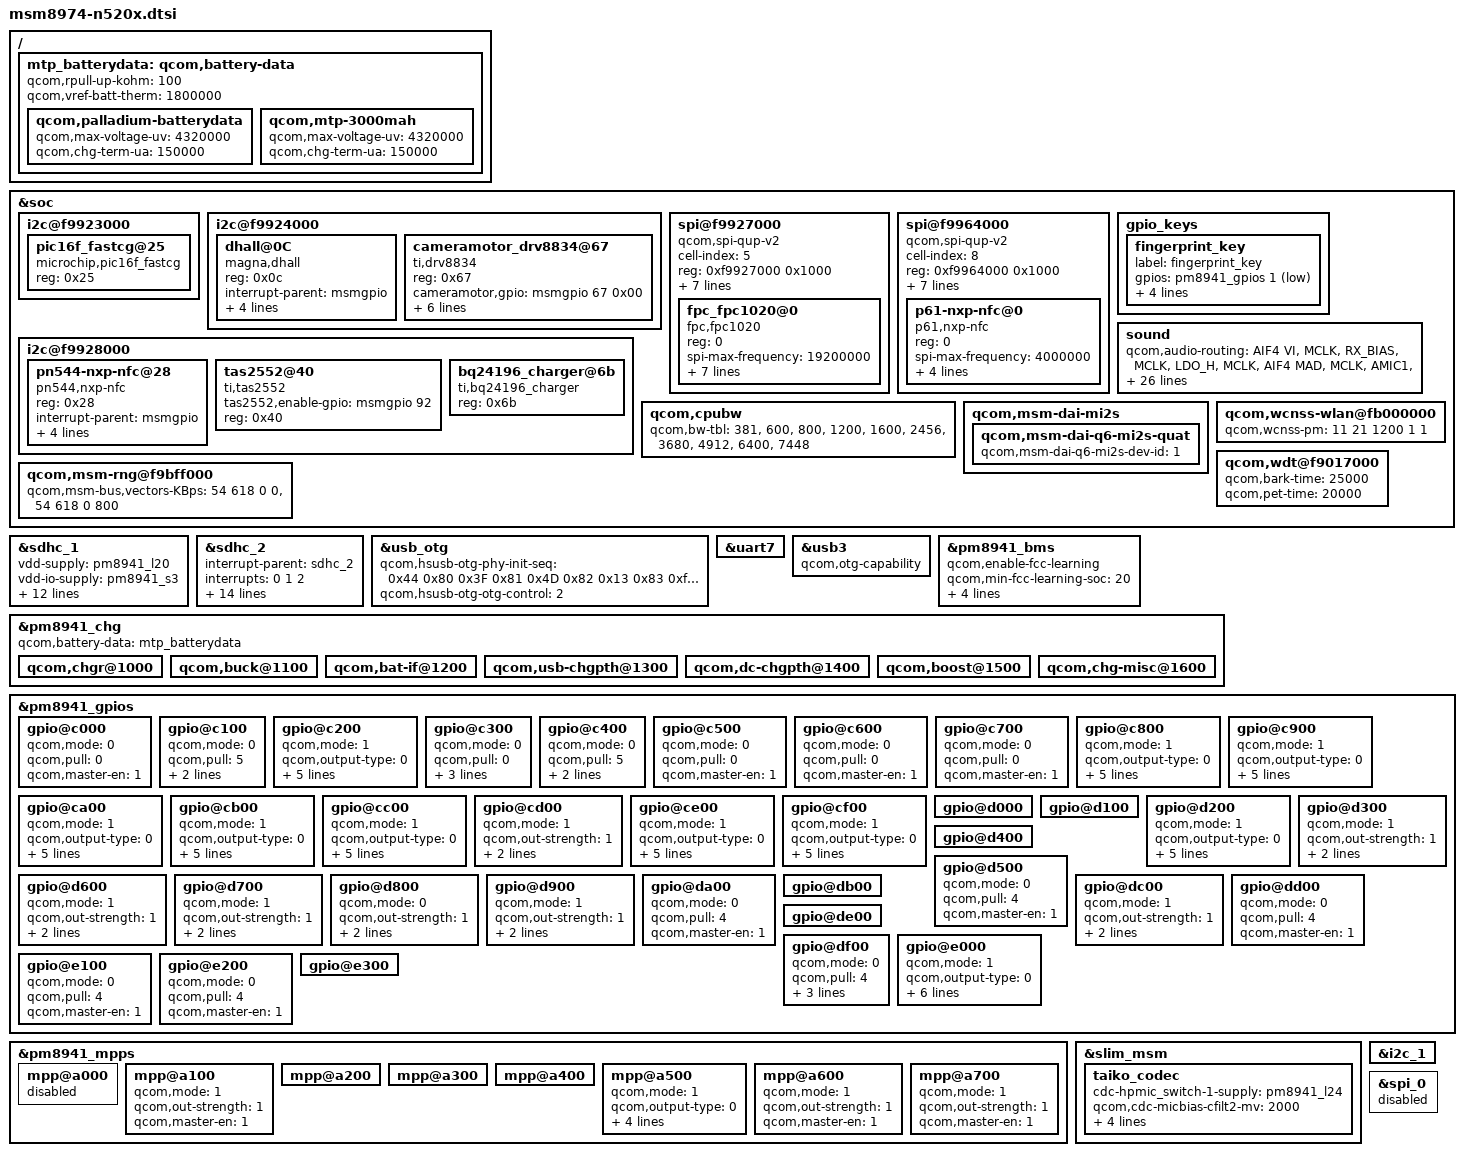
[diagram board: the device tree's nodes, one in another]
/* Copyright (c) 2012-2013, The Linux Foundation. All rights reserved.
 *
 * This program is free software; you can redistribute it and/or modify
 * it under the terms of the GNU General Public License version 2 and
 * only version 2 as published by the Free Software Foundation.
 *
 * This program is distributed in the hope that it will be useful,
 * but WITHOUT ANY WARRANTY; without even the implied warranty of
 * MERCHANTABILITY or FITNESS FOR A PARTICULAR PURPOSE.  See the
 * GNU General Public License for more details.
 */

/include/ "msm8974-oppo-common.dtsi"
/include/ "msm8974-oppo-camera.dtsi"
/include/ "msm8974-n520x-camera-sensor.dtsi"
/include/ "msm8974-oppo-input.dtsi"
/include/ "msm8974-oppo-usb.dtsi"
/include/ "msm8974-oppo-misc.dtsi"
/include/ "msm8974-oppo-pm.dtsi"
/include/ "msm8974-oppo-nfc.dtsi"
/include/ "msm8974-oppo-regulator.dtsi"
/include/ "msm8974-oppo-sound.dtsi"
/include/ "msm8974-oppo-leds.dtsi"
/include/ "msm8974-n520x-leds.dtsi"
/include/ "msm8974-n520x-mdss.dtsi"

&soc {
	i2c@f9923000 {
		pic16f_fastcg@25 {
			status = "okay";
			compatible = "microchip,pic16f_fastcg";
			reg = <0x25>;
		};
	};

	i2c@f9924000 {
		dhall@0C {
			compatible = "magna,dhall";
			reg = <0x0c>;
			interrupt-parent = <&msmgpio>;
			interrupts = <64 0x4>;
			dhall,irq-gpio = <&msmgpio 64 0x2008>;
			vdd_2v8-supply = <&pm8941_l17>;
			vcc_i2c_1v8-supply = <&pm8941_lvs2>;
		};

		cameramotor_drv8834@67 {
			compatible = "ti,drv8834";
			reg = <0x67>;
			cameramotor,gpio = <&msmgpio 67 0x00>;
			qcom,platform-vref-gpio = <&pm8941_gpios 9 0>;
			qcom,platform-sleep-gpio = <&pm8941_gpios 10 0>;
			qcom,platform-dir-gpio = <&pm8941_gpios 11 0>;
			qcom,platform-m0-gpio = <&pm8941_gpios 12 0>;
			qcom,platform-m1-gpio = <&pm8941_gpios 13 0>;
			qcom,platform-step-gpio = <&pm8941_gpios 33 0>;
		};
	};

	spi@f9927000 {
		compatible = "qcom,spi-qup-v2";

		cell-index = <5>;
		reg-names = "spi_physical";
		reg = <0xf9927000 0x1000>;
		interrupt-names = "spi5_irq";
		interrupts = <0 99 0>;

		spi-max-frequency = <9600000>;
		#address-cells = <1>;
		#size-cells = <0>;

		qcom,gpio-mosi = <&msmgpio 23 0>;
		qcom,gpio-miso = <&msmgpio 24 0>;
		qcom,gpio-clk  = <&msmgpio 26 0>;
		qcom,gpio-cs0  = <&msmgpio 25 0>;

		qcom,master-id = <86>;

		fpc_fpc1020@0 {
			compatible = "fpc,fpc1020";
			reg = <0>;
			spi-max-frequency = <19200000>;
			interrupt-parent = <&msmgpio>;
			interrupts = <102 0>;
			fpc,gpio_irq = <&msmgpio 102 0x00>;
			fpc,gpio_reset = <&msmgpio 84 0x00>; 
			fpc,gpio_envdd = <&msmgpio 16 0x00>;
			fpc,vddtx_mv;
			vdd_io-supply = <&pm8941_s3>;
		};
	};

	i2c@f9928000 {
		pn544-nxp-nfc@28 {
			compatible = "pn544,nxp-nfc";
			reg = <0x28>;
			interrupt-parent = <&msmgpio>;
			interrupts = <59 0x4>;
			pn544,irq-gpio = <&msmgpio 59 0x00>;
			pn544,enable-gpio = <&msmgpio 13 0x00>;
			pn544,update-gpio = <&msmgpio 12 0x00>;
		};

		tas2552@40 {
			status = "okay";
			compatible = "ti,tas2552";
			tas2552,enable-gpio = <&msmgpio 92 0x00>;
			reg = <0x40>;
		};

		bq24196_charger@6b {
			status = "okay";
			compatible = "ti,bq24196_charger";
			reg = <0x6b>;
		};
	};

	spi@f9964000 {
		compatible = "qcom,spi-qup-v2";

		cell-index = <8>;
		reg-names = "spi_physical";
		reg = <0xf9964000 0x1000>;
		interrupt-names = "spi8_irq";
		interrupts = <0 102 0>;

		spi-max-frequency = <19200000>;
		#address-cells = <1>;
		#size-cells = <0>;

		qcom,gpio-mosi = <&msmgpio 45 0>;
		qcom,gpio-miso = <&msmgpio 46 0>;
		qcom,gpio-clk  = <&msmgpio 48 0>;
		qcom,gpio-cs0  = <&msmgpio 47 0>;

		qcom,master-id = <84>;

		p61-nxp-nfc@0 {
			compatible = "p61,nxp-nfc";
			reg = <0>;
			spi-max-frequency = <4000000>;
			spi-cs-high;
			interrupt-parent = <&msmgpio>;
			interrupts = <34 0>;
			p61-nxp-nfc,irq-gpio = <&msmgpio 34 0x00>;
		};
	};

	gpio_keys {

		fingerprint_key {
			label = "fingerprint_key";
			gpios = <&pm8941_gpios 1 0x1>;
			linux,input-type = <1>;
			linux,code = <120>;
			gpio-key,wakeup;
			debounce-interval = <15>;
		};
	};

	sound {
		qcom,audio-routing =
			"AIF4 VI", "MCLK",
			"RX_BIAS", "MCLK",
			"LDO_H", "MCLK",
			"AIF4 MAD", "MCLK",
			"AMIC1", "MIC BIAS1 Internal1",
			"MIC BIAS1 Internal1", "Handset Mic",
			"AMIC2", "MIC BIAS2 External",
			"MIC BIAS2 External", "Headset Mic",
			"AMIC3", "MIC BIAS1 External",
			"MIC BIAS1 External", "Main Mic",
			"AMIC4", "MIC BIAS1 External",
			"MIC BIAS1 External", "Second Mic",
			"AMIC5", "MIC BIAS1 External",
			"MIC BIAS1 External", "ANC Mic",
			"DMIC1", "MIC BIAS1 External",
			"MIC BIAS1 External", "Digital Mic1",
			"DMIC2", "MIC BIAS1 External",
			"MIC BIAS1 External", "Digital Mic2",
			"DMIC3", "MIC BIAS3 External",
			"MIC BIAS3 External", "Digital Mic3",
			"DMIC4", "MIC BIAS3 External",
			"MIC BIAS3 External", "Digital Mic4",
			"DMIC5", "MIC BIAS4 External",
			"MIC BIAS4 External", "Digital Mic5",
			"DMIC6", "MIC BIAS4 External",
			"MIC BIAS4 External", "Digital Mic6",
			"Lineout_1 amp", "LINEOUT1",
			"Lineout_3 amp", "LINEOUT3";

		qcom,model = "msm8974-taiko-mtp-snd-card";
		qcom,cdc-micbias2-headset-only;
		qcom,mbhc-audio-jack-type = "4-pole-jack";
		qcom,us-euro-gpios = <&msmgpio 87 0>;
		qcom,yda145_ctr-gpio = <&msmgpio 77 0>;
		qcom,yda145_boost-gpio = <&msmgpio 67 0>;
		enable_spk-gpio = <&msmgpio 73 0>;
		cdc_spk-supply = <&pm8941_boost>;
	};

	qcom,cpubw {
		qcom,bw-tbl =
			<  381 /*  50 MHz */ >,
			<  600 /*  75 MHz */ >,
			<  800 /* 100 MHz */ >,
			< 1200 /* 150 MHz */ >,
			< 1600 /* 200 MHz */ >,
			< 2456 /* 307 MHz */ >,
			< 3680 /* 460 MHz */ >,
			< 4912 /* 614 MHz */ >,
			< 6400 /* 800 MHz */ >,
			< 7448 /* 931 MHz */ >;
	};

	qcom,msm-dai-mi2s {
		qcom,msm-dai-q6-mi2s-quat {
			qcom,msm-dai-q6-mi2s-dev-id = <1>;
		};
	};

	qcom,wcnss-wlan@fb000000 {
		qcom,wcnss-pm = <11 21 1200 1 1>;
	};

	qcom,msm-rng@f9bff000 {
		qcom,msm-bus,vectors-KBps =
				<54 618 0 0>,
				<54 618 0 800>;
	};

	qcom,wdt@f9017000 {
		qcom,bark-time = <25000>;
		qcom,pet-time = <20000>;
	};
};

&sdhc_1 {
	vdd-supply = <&pm8941_l20>;
	vdd-io-supply = <&pm8941_s3>;

	qcom,vdd-always-on;
	qcom,vdd-lpm-sup;
	qcom,vdd-voltage-level = <2950000 2950000>;
	qcom,vdd-current-level = <800 500000>;

	qcom,vdd-io-always-on;
	qcom,vdd-io-voltage-level = <1800000 1800000>;
	qcom,vdd-io-current-level = <250 154000>;

	qcom,pad-pull-on = <0x0 0x3 0x3>; /* no-pull, pull-up, pull-up */
	qcom,pad-pull-off = <0x0 0x3 0x3>; /* no-pull, pull-up, pull-up */
	qcom,pad-drv-on = <0x4 0x4 0x4>; /* 10mA, 10mA, 10mA */
	qcom,pad-drv-off = <0x0 0x0 0x0>; /* 2mA, 2mA, 2mA */

	qcom,nonremovable;
	status = "ok";
};

&sdhc_2 {
	#address-cells = <0>;
	interrupt-parent = <&sdhc_2>;
	interrupts = <0 1 2>;
	#interrupt-cells = <1>;
	interrupt-map-mask = <0xffffffff>;
	interrupt-map = <0 &intc 0 125 0
			1 &intc 0 221 0
			2 &msmgpio 77 0x3>;
	interrupt-names = "hc_irq", "pwr_irq", "status_irq";
	cd-gpios = <&msmgpio 77 0x1>;

	vdd-supply = <&pm8941_l21>;
	vdd-io-supply = <&pm8941_l13>;

	qcom,vdd-voltage-level = <2950000 2950000>;
	qcom,vdd-current-level = <9000 800000>;

	qcom,vdd-io-voltage-level = <1800000 2950000>;
	qcom,vdd-io-current-level = <6 22000>;

	qcom,pad-pull-on = <0x0 0x3 0x3>; /* no-pull, pull-up, pull-up */
	qcom,pad-pull-off = <0x0 0x3 0x3>; /* no-pull, pull-up, pull-up */
	qcom,pad-drv-on = <0x4 0x4 0x4>; /* 10mA, 10mA, 10mA */
	qcom,pad-drv-off = <0x0 0x0 0x0>; /* 2mA, 2mA, 2mA */
	status = "ok";
};

/* Drive strength recommendations for clock line from hardware team is 10 mA.
 * But since the driver has been been using the below values from the start
 * without any problems, continue to use those.
 */

&sdhc_1 {
	qcom,pad-drv-on = <0x7 0x4 0x4>; /* 16mA, 10mA, 10mA */
};

&sdhc_2 {
	qcom,pad-drv-on = <0x7 0x4 0x4>; /* 16mA, 10mA, 10mA */
};

&usb_otg {
	qcom,hsusb-otg-phy-init-seq = <0x44 0x80 0x3F 0x81 0x4D 0x82 0x13 0x83 0xffffffff>;
	qcom,hsusb-otg-otg-control = <2>;
};

&uart7 {
	status = "ok";
};

&usb3 {
	qcom,otg-capability;
};

/ {
	mtp_batterydata: qcom,battery-data {
		qcom,rpull-up-kohm = <100>;
		qcom,vref-batt-therm = <1800000>;

		/include/ "../batterydata-palladium.dtsi"
		/include/ "../batterydata-mtp-3000mah.dtsi"
	};
};

&mtp_batterydata {
	qcom,palladium-batterydata {
		qcom,max-voltage-uv = <4320000>;
		qcom,chg-term-ua = <150000>;
	};

	qcom,mtp-3000mah {
		qcom,max-voltage-uv = <4320000>;
		qcom,chg-term-ua = <150000>;
	};
};

&pm8941_bms {
	qcom,enable-fcc-learning;
	qcom,min-fcc-learning-soc = <20>;
	qcom,min-fcc-ocv-pc = <30>;
	qcom,min-fcc-learning-samples = <5>;
	qcom,fcc-resolution = <10>;
	status = "ok";
	qcom,battery-data = <&mtp_batterydata>;
};

&pm8941_chg {
	status = "ok";
	qcom,battery-data = <&mtp_batterydata>;

	qcom,chgr@1000 {
		status = "ok";
	};

	qcom,buck@1100 {
		status = "ok";
	};

	qcom,bat-if@1200 {
		status = "ok";
	};

	qcom,usb-chgpth@1300 {
		status = "ok";
	};

	qcom,dc-chgpth@1400 {
		status = "ok";
	};

	qcom,boost@1500 {
		status = "ok";
	};

	qcom,chg-misc@1600 {
		status = "ok";
	};
};

&pm8941_gpios {
	gpio@c000 { /* GPIO 1 */
		qcom,mode = <0>;        /* QPNP_PIN_MODE_DIG_IN */
		qcom,pull = <0>;        /* QPNP_PIN_PULL_UP_30  */
		qcom,master-en = <1>;
	};

	gpio@c100 { /* GPIO 2 */
		qcom,mode = <0>;        /* QPNP_PIN_MODE_DIG_IN */
		qcom,pull = <5>;        /* QPNP_PIN_PULL_NO */
		qcom,vin-sel = <2>;     /* QPNP_PIN_VIN2 */
		qcom,src-sel = <0>;	/* QPNP_PIN_SEL_FUNC_CONSTANT */
	};

	gpio@c200 { /* GPIO 3 */
		qcom,mode = <1>;		/* QPNP_PIN_MODE_DIG_OUT */
		qcom,output-type = <0>;		/* QPNP_PIN_OUT_BUF_CMOS */
		qcom,pull = <5>;		/* QPNP_PIN_PULL_NO */
		qcom,vin-sel = <2>;		/* QPNP_PIN_VIN2 */
		qcom,out-strength = <3>;
		qcom,src-sel = <2>;
		qcom,master-en = <1>;
	};

	gpio@c300 { /* GPIO 4 */
		qcom,mode = <0>;        /* QPNP_PIN_MODE_DIG_IN */
		qcom,pull = <0>;        /* QPNP_PIN_PULL_UP_30  */
		qcom,vin-sel = <2>;     /* QPNP_PIN_VIN2  */
		qcom,src-sel = <0>;	/* QPNP_PIN_SEL_FUNC_CONSTANT */
		qcom,master-en = <1>;
	};

	gpio@c400 { /* GPIO 5 */
		qcom,mode = <0>;        /* QPNP_PIN_MODE_DIG_IN */
		qcom,pull = <5>;        /* QPNP_PIN_PULL_NO */
		qcom,vin-sel = <2>;     /* QPNP_PIN_VIN2 */
		qcom,src-sel = <0>;	/* QPNP_PIN_SEL_FUNC_CONSTANT */
	};

	gpio@c500 { /* GPIO 6 */
		qcom,mode = <0>;        /* QPNP_PIN_MODE_DIG_IN */
		qcom,pull = <0>;        /* QPNP_PIN_PULL_UP_30  */
		qcom,master-en = <1>;
	};

	gpio@c600 { /* GPIO 7 */
		qcom,mode = <0>;        /* QPNP_PIN_MODE_DIG_IN */
		qcom,pull = <0>;        /* QPNP_PIN_PULL_UP_30  */
		qcom,master-en = <1>;
	};

	gpio@c700 { /* GPIO 8 */
		qcom,mode = <0>;        /* QPNP_PIN_MODE_DIG_IN */
		qcom,pull = <0>;        /* QPNP_PIN_PULL_UP_30  */
		qcom,master-en = <1>;
	};

	gpio@c800 { /* GPIO 9 */
		qcom,mode = <1>;		/* QPNP_PIN_MODE_DIG_OUT */
		qcom,output-type = <0>;		/* QPNP_PIN_OUT_BUF_CMOS */
		qcom,pull = <5>;		/* QPNP_PIN_PULL_NO */
		qcom,vin-sel = <0>;		/* QPNP_PIN_VIN2 VPH_PWR */
		qcom,out-strength = <1>;	/* QPNP_PIN_OUT_STRENGTH_LOW */
		qcom,src-sel = <0>;		/* QPNP_PIN_SEL_FUNC_CONSTANT */
		qcom,master-en = <0>;
	};

	gpio@c900 { /* GPIO 10 */
		qcom,mode = <1>;		/* QPNP_PIN_MODE_DIG_OUT */
		qcom,output-type = <0>;		/* QPNP_PIN_OUT_BUF_CMOS */
		qcom,pull = <5>;		/* QPNP_PIN_PULL_NO */
		qcom,vin-sel = <0>;		/* QPNP_PIN_VIN2 */
		qcom,out-strength = <1>;	/* QPNP_PIN_OUT_STRENGTH_LOW */
		qcom,src-sel = <0>;		/* QPNP_PIN_SEL_FUNC_CONSTANT */
		qcom,master-en = <1>;
	};

	gpio@ca00 { /* GPIO 11 */
		qcom,mode = <1>;		/* QPNP_PIN_MODE_DIG_OUT */
		qcom,output-type = <0>;		/* QPNP_PIN_OUT_BUF_CMOS */
		qcom,pull = <5>;		/* QPNP_PIN_PULL_NO */
		qcom,vin-sel = <0>;		/* QPNP_PIN_VIN2 */
		qcom,out-strength = <1>;	/* QPNP_PIN_OUT_STRENGTH_LOW */
		qcom,src-sel = <0>;		/* QPNP_PIN_SEL_FUNC_CONSTANT */
		qcom,master-en = <1>;
	};

	gpio@cb00 { /* GPIO 12 */
		qcom,mode = <1>;		/* QPNP_PIN_MODE_DIG_OUT */
		qcom,output-type = <0>;		/* QPNP_PIN_OUT_BUF_CMOS */
		qcom,pull = <5>;		/* QPNP_PIN_PULL_NO */
		qcom,vin-sel = <0>;		/* QPNP_PIN_VIN2 */
		qcom,out-strength = <1>;	/* QPNP_PIN_OUT_STRENGTH_LOW */
		qcom,src-sel = <0>;		/* QPNP_PIN_SEL_FUNC_CONSTANT */
		qcom,master-en = <1>;
	};

	gpio@cc00 { /* GPIO 13 */
		qcom,mode = <1>;		/* QPNP_PIN_MODE_DIG_OUT */
		qcom,output-type = <0>;		/* QPNP_PIN_OUT_BUF_CMOS */
		qcom,pull = <5>;		/* QPNP_PIN_PULL_NO */
		qcom,vin-sel = <0>;		/* QPNP_PIN_VIN2 */
		qcom,out-strength = <1>;	/* QPNP_PIN_OUT_STRENGTH_LOW */
		qcom,src-sel = <0>;		/* QPNP_PIN_SEL_FUNC_CONSTANT */
		qcom,master-en = <1>;
	};

	gpio@cd00 { /* GPIO 14 */
		qcom,mode = <1>;          /* QPNP_PIN_MODE_DIG_OUT */
		qcom,out-strength = <1>;  /* QPNP_PIN_OUT_STRENGTH_LOW */
		qcom,src-sel = <2>;       /* QPNP_PIN_SEL_FUNC_1  */
		qcom,master-en = <1>;
	};

	gpio@ce00 { /* GPIO 15 */
		qcom,mode = <1>;
		qcom,output-type = <0>;
		qcom,pull = <5>;
		qcom,vin-sel = <2>;
		qcom,out-strength = <1>;
		qcom,src-sel = <2>;
		qcom,master-en = <1>;
	};

	gpio@cf00 { /* GPIO 16 */
		qcom,mode = <1>;
		qcom,output-type = <0>;
		qcom,pull = <5>;
		qcom,vin-sel = <2>;
		qcom,out-strength = <3>;
		qcom,src-sel = <3>;       /* QPNP_PIN_SEL_FUNC_2  */
		qcom,master-en = <1>;
	};

	gpio@d000 { /* GPIO 17 */
	};

	gpio@d100 { /* GPIO 18 */
	};

	gpio@d200 { /* GPIO 19 */
		qcom,mode = <1>;		/* QPNP_PIN_MODE_DIG_OUT */
		qcom,output-type = <0>;		/* QPNP_PIN_OUT_BUF_CMOS */
		qcom,pull = <5>;		/* QPNP_PIN_PULL_NO */
		qcom,vin-sel = <2>;		/* QPNP_PIN_VIN2 */
		qcom,out-strength = <1>;	/* QPNP_PIN_OUT_STRENGTH_LOW */
		qcom,src-sel = <0>;		/* QPNP_PIN_SEL_FUNC_CONSTANT */
		qcom,master-en = <1>;
	};

	gpio@d300 { /* GPIO 20 */
		qcom,mode = <1>;          /* QPNP_PIN_MODE_DIG_OUT */
		qcom,out-strength = <1>;  /* QPNP_PIN_OUT_STRENGTH_LOW */
		qcom,src-sel = <2>;       /* QPNP_PIN_SEL_FUNC_1  */
		qcom,master-en = <1>;
	};

	gpio@d400 { /* GPIO 21 */
	};

	gpio@d500 { /* GPIO 22 */
		qcom,mode = <0>;        /* QPNP_PIN_MODE_DIG_IN */
		qcom,pull = <4>;	/* QPNP_PIN_PULL_DN */
		qcom,master-en = <1>;
	};

	gpio@d600 { /* GPIO 23 */
		qcom,mode = <1>;          /* QPNP_PIN_MODE_DIG_OUT */
		qcom,out-strength = <1>;  /* QPNP_PIN_OUT_STRENGTH_LOW */
		qcom,src-sel = <2>;       /* QPNP_PIN_SEL_FUNC_1  */
		qcom,master-en = <1>;
	};

	gpio@d700 { /* GPIO 24 */
		qcom,mode = <1>;          /* QPNP_PIN_MODE_DIG_OUT */
		qcom,out-strength = <1>;  /* QPNP_PIN_OUT_STRENGTH_LOW */
		qcom,src-sel = <2>;       /* QPNP_PIN_SEL_FUNC_1  */
		qcom,master-en = <1>;
	};

	gpio@d800 { /* GPIO 25 */
		qcom,mode = <0>;          /* QPNP_PIN_MODE_DIG_IN */
		qcom,out-strength = <1>;  /* QPNP_PIN_OUT_STRENGTH_LOW */
		qcom,src-sel = <2>;       /* QPNP_PIN_SEL_FUNC_1  */
		qcom,master-en = <1>;
	};

	gpio@d900 { /* GPIO 26 */
		qcom,mode = <1>;          /* QPNP_PIN_MODE_DIG_OUT */
		qcom,out-strength = <1>;  /* QPNP_PIN_OUT_STRENGTH_LOW */
		qcom,src-sel = <2>;       /* QPNP_PIN_SEL_FUNC_1  */
		qcom,master-en = <1>;
	};

	gpio@da00 { /* GPIO 27 */
		qcom,mode = <0>;        /* QPNP_PIN_MODE_DIG_IN */
		qcom,pull = <4>;	/* QPNP_PIN_PULL_DN */
		qcom,master-en = <1>;
	};

	gpio@db00 { /* GPIO 28 */
	};

	gpio@dc00 { /* GPIO 29 */
		qcom,mode = <1>;          /* QPNP_PIN_MODE_DIG_OUT */
		qcom,out-strength = <1>;  /* QPNP_PIN_OUT_STRENGTH_LOW */
		qcom,src-sel = <2>;       /* QPNP_PIN_SEL_FUNC_1  */
		qcom,master-en = <1>;
	};

	gpio@dd00 { /* GPIO 30 */
		qcom,mode = <0>;        /* QPNP_PIN_MODE_DIG_IN */
		qcom,pull = <4>;	/* QPNP_PIN_PULL_DN */
		qcom,master-en = <1>;
	};

	gpio@de00 { /* GPIO 31 */
	};

	gpio@df00 { /* GPIO 32 */
		qcom,mode = <0>;        /* QPNP_PIN_MODE_DIG_IN */
		qcom,pull = <4>;	/* QPNP_PIN_PULL_DN */
		qcom,vin-sel = <2>;     /* QPNP_PIN_VIN2  */
		qcom,src-sel = <0>;     /* QPNP_PIN_SEL_FUNC_CONSTANT */
		qcom,master-en = <1>;
	};

	gpio@e000 { /* GPIO 33 */
		qcom,mode = <1>;	/* QPNP_PIN_MODE_DIG_OUT */
		qcom,output-type = <0>;	/* QPNP_PIN_OUT_BUF_CMOS */
		qcom,invert = <0>;	/* QPNP_PIN_INVERT_DISABLE */
		qcom,pull = <5>;	/* QPNP_PIN_PULL_NO */
		qcom,vin-sel = <0>;	/* QPNP_PIN_VIN2, VREG_S3A */
		qcom,out-strength = <2>;/* QPNP_PIN_OUT_STRENGTH_MED */
		qcom,src-sel = <3>;	/* QPNP_PIN_SEL_FUNC_2 */
		qcom,master-en = <1>;
	};

	gpio@e100 { /* GPIO 34 */
		qcom,mode = <0>;        /* QPNP_PIN_MODE_DIG_IN */
		qcom,pull = <4>;	/* QPNP_PIN_PULL_DN */
		qcom,master-en = <1>;
	};

	gpio@e200 { /* GPIO 35 */
		qcom,mode = <0>;        /* QPNP_PIN_MODE_DIG_IN */
		qcom,pull = <4>;	/* QPNP_PIN_PULL_DN */
		qcom,master-en = <1>;
	};

	gpio@e300 { /* GPIO 36 */
	};
};

&pm8941_mpps {

	mpp@a000 { /* MPP 1 */
		status = "disabled";
	};

	mpp@a100 { /* MPP 2 */
		qcom,mode = <1>;          /* QPNP_PIN_MODE_DIG_OUT */
		qcom,out-strength = <1>;  /* QPNP_PIN_OUT_STRENGTH_LOW */
		qcom,master-en = <1>;
	};

	mpp@a200 { /* MPP 3 */
	};

	mpp@a300 { /* MPP 4 */
	};

	mpp@a400 { /* MPP 5 */
	};

	mpp@a500 { /* MPP 6 */
		/* SPI_ETH_RST config */
		qcom,mode = <1>; /* DIG_OUT */
		qcom,output-type = <0>; /* CMOS */
		qcom,vin-sel = <2>; /* PM8941_S3 1.8V > 1.6V */
		qcom,src-sel = <0>; /* CONSTANT */
		qcom,out-strength = <1>;  /* QPNP_PIN_OUT_STRENGTH_LOW */
		qcom,master-en = <1>; /* ENABLE MPP */
	};

	mpp@a600 { /* MPP 7 */
		qcom,mode = <1>;          /* QPNP_PIN_MODE_DIG_OUT */
		qcom,out-strength = <1>;  /* QPNP_PIN_OUT_STRENGTH_LOW */
		qcom,master-en = <1>;
	};

	mpp@a700 { /* MPP 8 */
		qcom,mode = <1>;          /* QPNP_PIN_MODE_DIG_OUT */
		qcom,out-strength = <1>;  /* QPNP_PIN_OUT_STRENGTH_LOW */
		qcom,master-en = <1>;
	};
};

&slim_msm {
	taiko_codec {
		cdc-hpmic_switch-1-supply = <&pm8941_l24>;
		qcom,cdc-micbias-cfilt2-mv = <2000>;
		qcom,cdc-micbias1-ext-cap;
		qcom,cdc-micbias2-ext-cap;
		qcom,cdc-micbias3-ext-cap;
		qcom,cdc-micbias4-ext-cap;
	};
};

&i2c_1 {
	status = "ok";
};

&spi_0 {
	status = "disabled";
};
